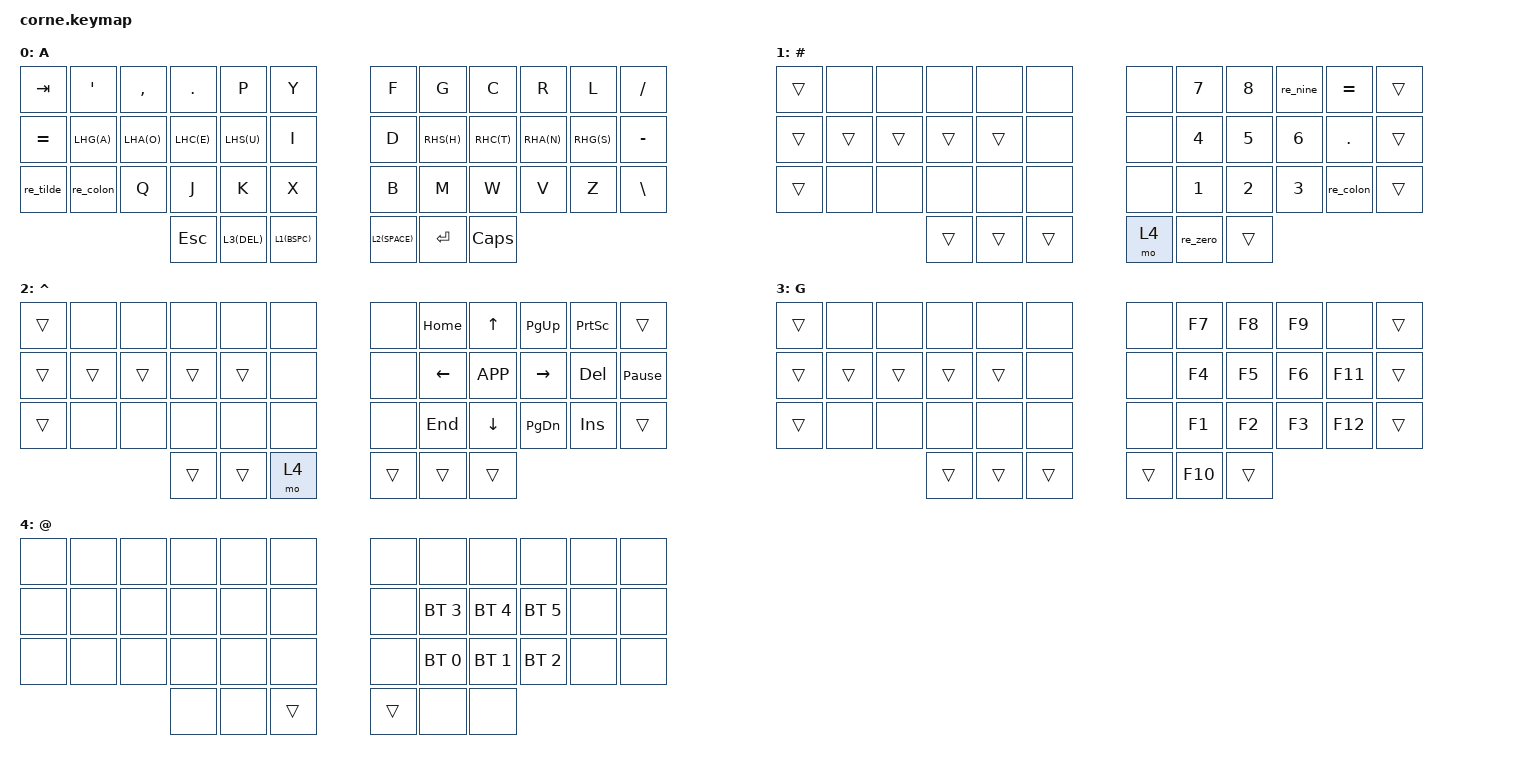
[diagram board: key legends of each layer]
/*
 * Copyright (c) 2020 The ZMK Contributors
 *
 * SPDX-License-Identifier: MIT
 *
 */

#include <behaviors.dtsi>
#include <dt-bindings/zmk/keys.h>
#include <dt-bindings/zmk/bt.h>
#include "42-keys.h"

#define ___ &trans
#define XXX &none
#define L1(key) &lt 1 key
#define L2(key) &lt 2 key
#define L3(key) &lt 3 key
#define L4(key) &lt 4 key

#define LHG(key) &hml LGUI key
#define LHA(key) &hml LALT key
#define LHC(key) &hml LCTL key
#define LHS(key) &hml LSFT key

#define RHG(key) &hmr RGUI key
#define RHA(key) &hmr RALT key
#define RHC(key) &hmr RCTL key
#define RHS(key) &hmr RSFT key

&mt {
	tapping-term-ms = <175>;
	quick-tap-ms = <150>;
};

/ {
	macros {
		#include "macros.dtsi"
	};

	behaviors {
		#include "swapped-keys.dtsi"
		hml: homerow_mods_left {
			compatible = "zmk,behavior-hold-tap";
			#binding-cells = <2>;
			flavor = "balanced";
			tapping-term-ms = <280>;
			quick-tap-ms = <150>;
			require-prior-idle-ms = <100>;
			bindings = <&kp>, <&kp>;
			hold-trigger-key-positions = RIGHT_SIDE;
			hold-trigger-on-release;
		};
		hmr: homerow_mods_right {
			compatible = "zmk,behavior-hold-tap";
			#binding-cells = <2>;
			flavor = "balanced";
			tapping-term-ms = <280>;
			quick-tap-ms = <150>;
			require-prior-idle-ms = <100>;
			bindings = <&kp>, <&kp>;
			hold-trigger-key-positions = LEFT_SIDE;
			hold-trigger-on-release;
		};
	};

	combos {
		compatible = "zmk,combos";
		#include "combos.dtsi"
	};

	keymap {
		compatible = "zmk,keymap";
		default_layer {
			display-name = "A";
			/*	L5	L4	L3	L2	L1	L0	R0	R1	R2	R3	R4	R5
			 *  T	TAB	'	,	.	P	Y	F	G	C	R	L	/
			 *  M	=	A	O	E	U	I	D	H	T	N	S	-
			 *  B	~	:	Q	J	K	X	B	M	W	V	Z	\
			 *  H				ESC	DEL	BSP	SPC	RET	CAPS
			 */
			bindings = <
				&kp TAB &kp SQT &kp COMMA &kp DOT &kp P &kp Y &kp F &kp G &kp C &kp R &kp L &kp FSLH
				&kp EQUAL LHG(A) LHA(O) LHC(E) LHS(U) &kp I &kp D RHS(H) RHC(T) RHA(N) RHG(S) &kp MINUS
				&re_tilde &re_colon &kp Q &kp J &kp K &kp X &kp B &kp M &kp W &kp V &kp Z &kp BSLH
				&kp ESC L3(DEL) L1(BSPC) L2(SPACE) &kp RET &kp CAPS
				>;
		};
		num_layer {
			display-name = "#";
			/*
			 *	___	XXX	XXX	XXX	XXX	XXX	XXX	7	8	9	=	___
			 *	___	___	___	___	___	XXX	XXX	4	5	6	.	___
			 *	___	XXX	XXX	XXX	XXX	XXX	XXX	1	2	3	:	___
			 *				___	___	___	LY4	0	___
			 */
			bindings = <
				___ XXX XXX XXX XXX XXX XXX &kp N7 &kp N8 &re_nine &kp EQUAL ___
				___ ___ ___ ___ ___ XXX XXX &kp N4 &kp N5 &kp N6 &kp DOT ___
				___ XXX XXX XXX XXX XXX XXX &kp N1 &kp N2 &kp N3 &re_colon ___
				___ ___ ___ &mo 4 &re_zero ___
				>;
		};
		nav_layer {
			display-name = "^";
			/*
			 *	___	XXX	XXX	XXX	XXX	XXX	XXX	HOM	UP	PUP	PSC	___
			 *	___	___	___	___	___	XXX	XXX	LFT	APP	RHT	DEL	PAUSE/BREAK
			 *	___	XXX	XXX	XXX	XXX	XXX	XXX	END	DN	PDN	INS	___
			 *				___	___	LY4	___	___	___
			 */
			bindings = <
				___ XXX XXX XXX XXX XXX XXX &kp HOME &kp UP &kp PG_UP &kp PSCRN ___
				___ ___ ___ ___ ___ XXX XXX &kp LEFT &kp K_APP &kp RIGHT &kp DEL &kp PAUSE_BREAK
				___ XXX XXX XXX XXX XXX XXX &kp END &kp DOWN &kp PG_DN &kp INS ___
				___ ___ &mo 4 ___ ___ ___
				>;
		};
		fun_layer {
			display-name = "G";
			/*
			 *	___	XXX	XXX	XXX	XXX	XXX	XXX	F7	F8	F9	XXX	___
			 *	___	___	___	___	___	XXX	XXX	F4	F5	F6	F11	___
			 *	___	XXX	XXX	XXX	XXX	XXX	XXX	F1	F2	F3	F12	___
			 *				___	___	___	___	F10	___
			 */
			bindings = <
				___ XXX XXX XXX XXX XXX XXX &kp F7 &kp F8 &kp F9 XXX ___
				___ ___ ___ ___ ___ XXX XXX &kp F4 &kp F5 &kp F6 &kp F11 ___
				___ XXX XXX XXX XXX XXX XXX &kp F1 &kp F2 &kp F3 &kp F12 ___
				___ ___ ___ ___ &kp F10 ___
				>;
		};
		bt_layer {
			display-name = "@";
			/*
			 *	XXX	XXX	XXX	XXX	XXX	XXX	XXX	XXX	XXX	XXX	XXX	XXX
			 *	XXX	XXX	XXX	XXX	XXX	XXX	XXX	BT4	BT5	BT6	XXX	XXX
			 *	XXX	XXX	XXX	XXX	XXX	XXX	XXX	BT1	BT2	BT3	XXX	XXX
			 *				XXX	XXX	___	___	XXX	XXX
			 */
			bindings = <
				XXX XXX XXX XXX XXX XXX XXX XXX XXX XXX XXX XXX
				XXX XXX XXX XXX XXX XXX XXX &bt BT_SEL 3 &bt BT_SEL 4 &bt BT_SEL 5 XXX XXX
				XXX XXX XXX XXX XXX XXX XXX &bt BT_SEL 0 &bt BT_SEL 1 &bt BT_SEL 2 XXX XXX
				XXX XXX ___ ___ XXX XXX
				>;
		};
	};
};
